# PIC16F1829 register map
File version: 1.0
PIC16F1829 special function registers
Registers are 8-bit, read-write, reset 0x0 unless marked. A register's access mark holds for its fields unless they carry their own. Offsets are from the block's base; lines under a group give offsets from that group; [hi:lo] are bit positions; {n}, {i} and the like mark numbered series; 'fields as' and 'values as' point back to an identical list; <NAME> marks a mode.

## Memory map
0x00800000 CPU size 0xFF0 — Core registers
0x0080000C PORTA size 0x388
0x0080000D PORTB size 0x38A
0x0080000E PORTC size 0x381
0x00800011 INTERRUPTS size 0x84 — Interrupt flags and enables
0x00800015 TIMER0 size 0x1
0x00800016 TIMER1 size 0x4
0x0080001A TIMER2 size 0x3
0x0080001E CAPSENSE size 0x2 — Capacitive sensing
0x00800095 SYSTEM size 0x8A — Reset, watchdog and pin options
0x00800098 OSCILLATOR size 0x303
0x0080009B ADC size 0x4 — Analog-to-digital converter
0x00800111 COMPARATORS size 0x5
0x00800117 REFERENCES size 0x5 — Voltage reference, DAC and SR latch
0x00800191 NVM size 0x6 — Flash and EEPROM access
0x00800199 EUSART size 0x7
0x00800211 MSSP size 0xF — Synchronous serial port
0x00800291 CCP size 0x8A — Capture, compare and PWM
0x0080039C OTHER size 0x4 — Other registers
0x00800415 TIMER4 size 0x3
0x0080041C TIMER6 size 0x3

## CPU — Core registers
Base 0x00800000
0x00 INDF0 reset not defined — INDF0, data address 0x000
0x01 INDF1 reset not defined — INDF1, data address 0x001
0x02 PCL — PCL, data address 0x002
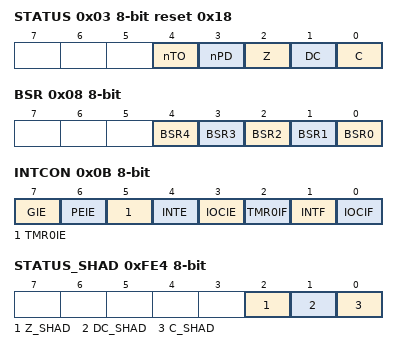
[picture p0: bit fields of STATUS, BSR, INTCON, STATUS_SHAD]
0x03 STATUS reset 0x18 — STATUS, data address 0x003
  [4] nTO, [3] nPD, [2] Z, [1] DC, [0] C
0x04 FSR0L — FSR0L, data address 0x004
0x05 FSR0H — FSR0H, data address 0x005
0x06 FSR1L — FSR1L, data address 0x006
0x07 FSR1H — FSR1H, data address 0x007
0x08 BSR — BSR, data address 0x008
  [n] BSR{n} (n=0..4)
0x09 WREG — WREG, data address 0x009
  [7:0] WREG0
0x0A PCLATH — PCLATH, data address 0x00a
  [6:0] PCLATH
0x0B INTCON — INTCON, data address 0x00b
  [7] GIE, [6] PEIE, [5] TMR0IE, [4] INTE, [3] IOCIE, [2] TMR0IF, [1] INTF, [0] IOCIF
0xFE4 STATUS_SHAD reset not defined — STATUS_SHAD, data address 0xfe4
  [2] Z_SHAD, [1] DC_SHAD, [0] C_SHAD
0xFE5 WREG_SHAD reset not defined — WREG_SHAD, data address 0xfe5
0xFE6 BSR_SHAD reset not defined — BSR_SHAD, data address 0xfe6
  [4:0] BSR_SHAD
0xFE7 PCLATH_SHAD reset not defined — PCLATH_SHAD, data address 0xfe7
  [6:0] PCLATH_SHAD
0xFE8 FSR0L_SHAD reset not defined — FSR0L_SHAD, data address 0xfe8
0xFE9 FSR0H_SHAD reset not defined — FSR0H_SHAD, data address 0xfe9
0xFEA FSR1L_SHAD reset not defined — FSR1L_SHAD, data address 0xfea
0xFEB FSR1H_SHAD reset not defined — FSR1H_SHAD, data address 0xfeb
0xFED STKPTR reset 0x1F — STKPTR, data address 0xfed
  [4:0] STKPTR
0xFEE TOSL reset not defined — TOSL, data address 0xfee
0xFEF TOSH reset not defined — TOSH, data address 0xfef
  [6:0] TOSH

## ADC — Analog-to-digital converter
Base 0x0080009B
0x00 ADRESL reset not defined — ADRESL, data address 0x09b
0x01 ADRESH reset not defined — ADRESH, data address 0x09c
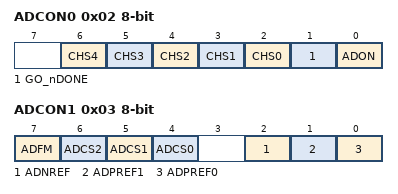
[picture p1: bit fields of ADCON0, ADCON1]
0x02 ADCON0 — ADCON0, data address 0x09d
  [n+2] CHS{n} (n=0..4), [1] GO_nDONE, [0] ADON
0x03 ADCON1 — ADCON1, data address 0x09e
  [7] ADFM, [6] ADCS2, [5] ADCS1, [4] ADCS0, [2] ADNREF, [1] ADPREF1, [0] ADPREF0

## CAPSENSE — Capacitive sensing
Base 0x0080001E
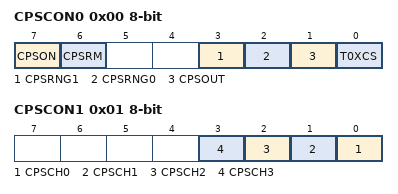
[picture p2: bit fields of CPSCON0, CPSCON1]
0x00 CPSCON0 (reset mask 0x8F) — CPSCON0, data address 0x01e
  [7] CPSON, [6] CPSRM, [3] CPSRNG1, [2] CPSRNG0, [1] CPSOUT, [0] T0XCS
0x01 CPSCON1 — CPSCON1, data address 0x01f
  [n] CPSCH{n} (n=0..3)

## CCP — Capture, compare and PWM
Base 0x00800291
0x00 CCPR1L reset not defined — CCPR1L, data address 0x291
0x01 CCPR1H reset not defined — CCPR1H, data address 0x292
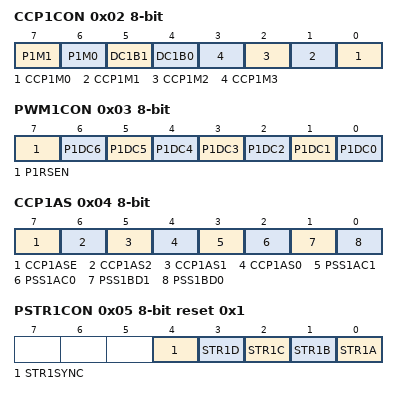
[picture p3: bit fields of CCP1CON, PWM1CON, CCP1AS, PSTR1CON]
0x02 CCP1CON — CCP1CON, data address 0x293
  [7] P1M1, [6] P1M0, [5] DC1B1, [4] DC1B0, [n] CCP1M{n} (n=0..3)
0x03 PWM1CON — PWM1CON, data address 0x294
  [7] P1RSEN, [n] P1DC{n} (n=0..6)
0x04 CCP1AS — CCP1AS, data address 0x295
  [7] CCP1ASE, [6] CCP1AS2, [5] CCP1AS1, [4] CCP1AS0, [3] PSS1AC1, [2] PSS1AC0, [1] PSS1BD1, [0] PSS1BD0
0x05 PSTR1CON reset 0x1 — PSTR1CON, data address 0x296
  [4] STR1SYNC, [3] STR1D, [2] STR1C, [1] STR1B, [0] STR1A
0x07 CCPR2L reset not defined — CCPR2L, data address 0x298
0x08 CCPR2H reset not defined — CCPR2H, data address 0x299
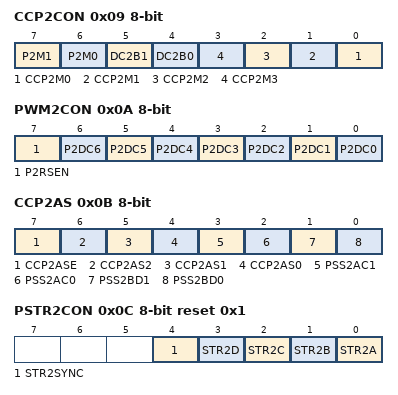
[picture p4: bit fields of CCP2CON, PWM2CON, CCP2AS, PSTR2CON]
0x09 CCP2CON — CCP2CON, data address 0x29a
  [7] P2M1, [6] P2M0, [5] DC2B1, [4] DC2B0, [n] CCP2M{n} (n=0..3)
0x0A PWM2CON — PWM2CON, data address 0x29b
  [7] P2RSEN, [n] P2DC{n} (n=0..6)
0x0B CCP2AS — CCP2AS, data address 0x29c
  [7] CCP2ASE, [6] CCP2AS2, [5] CCP2AS1, [4] CCP2AS0, [3] PSS2AC1, [2] PSS2AC0, [1] PSS2BD1, [0] PSS2BD0
0x0C PSTR2CON reset 0x1 — PSTR2CON, data address 0x29d
  [4] STR2SYNC, [3] STR2D, [2] STR2C, [1] STR2B, [0] STR2A
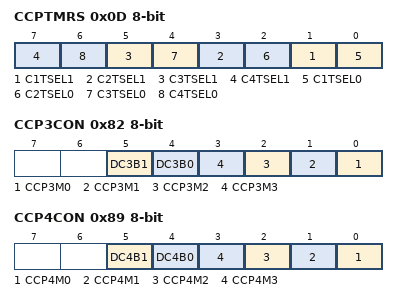
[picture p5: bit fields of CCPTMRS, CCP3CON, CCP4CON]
0x0D CCPTMRS — CCPTMRS, data address 0x29e
  [2n-1] C{n}TSEL1 (n=1..4), [2n-2] C{n}TSEL0 (n=1..4)
0x80 CCPR3L reset not defined — CCPR3L, data address 0x311
0x81 CCPR3H reset not defined — CCPR3H, data address 0x312
0x82 CCP3CON — CCP3CON, data address 0x313
  [5] DC3B1, [4] DC3B0, [n] CCP3M{n} (n=0..3)
0x87 CCPR4L reset not defined — CCPR4L, data address 0x318
0x88 CCPR4H reset not defined — CCPR4H, data address 0x319
0x89 CCP4CON — CCP4CON, data address 0x31a
  [5] DC4B1, [4] DC4B0, [n] CCP4M{n} (n=0..3)
